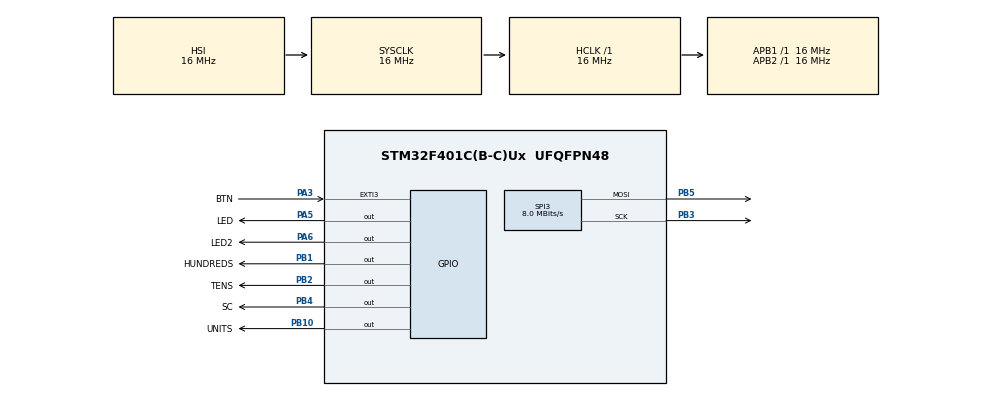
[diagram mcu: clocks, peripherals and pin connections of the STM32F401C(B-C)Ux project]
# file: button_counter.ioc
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Mcu.Family=STM32F4
Mcu.Name=STM32F401C(B-C)Ux
Mcu.Package=UFQFPN48
NVIC.EXTI3_IRQn=true\:0\:0\:false\:false\:true\:true\:true\:true
NVIC.PriorityGroup=NVIC_PRIORITYGROUP_4
PA13.Mode=Serial_Wire
PA13.Signal=SYS_JTMS-SWDIO
PA14.Mode=Serial_Wire
PA14.Signal=SYS_JTCK-SWCLK
PA3.GPIO_Label=BTN
PA3.GPIO_PuPd=GPIO_PULLDOWN
PA3.Signal=GPXTI3
PA5.GPIO_Label=LED
PA5.Signal=GPIO_Output
PA6.GPIO_Label=LED2
PA6.Signal=GPIO_Output
PB1.GPIO_Label=HUNDREDS
PB1.Signal=GPIO_Output
PB10.GPIO_Label=UNITS
PB10.Signal=GPIO_Output
PB2.GPIO_Label=TENS
PB2.Signal=GPIO_Output
PB3.Mode=TX_Only_Simplex_Unidirect_Master
PB3.Signal=SPI3_SCK
PB4.GPIO_Label=SC
PB4.Signal=GPIO_Output
PB5.Mode=TX_Only_Simplex_Unidirect_Master
PB5.Signal=SPI3_MOSI
ProjectManager.HeapSize=0x200
ProjectManager.StackSize=0x400
ProjectManager.TargetToolchain=STM32CubeIDE
RCC.AHBFreq_Value=16000000
RCC.APB1Freq_Value=16000000
RCC.APB2Freq_Value=16000000
RCC.CortexFreq_Value=16000000
RCC.HSE_VALUE=25000000
RCC.HSI_VALUE=16000000
RCC.LSE_VALUE=32768
RCC.SYSCLKFreq_VALUE=16000000
RCC.VCOOutputFreq_Value=192000000
SPI3.CalculateBaudRate=8.0 MBits/s
SPI3.Direction=SPI_DIRECTION_2LINES
SPI3.Mode=SPI_MODE_MASTER
SPI3.VirtualType=VM_MASTER
board=custom

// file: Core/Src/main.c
/* USER CODE BEGIN Header */
/**
  ******************************************************************************
  * @file           : main.c
  * @brief          : Main program body
  ******************************************************************************
  * @attention
  *
  * Copyright (c) 2025 STMicroelectronics.
  * All rights reserved.
  *
  * This software is licensed under terms that can be found in the LICENSE file
  * in the root directory of this software component.
  * If no LICENSE file comes with this software, it is provided AS-IS.
  *
  ******************************************************************************
  */
/* USER CODE END Header */
#include "main.h"

/* USER CODE BEGIN Includes */
#include "btn_counter.h" // Custom header for button counter logic / Пользовательский заголовок для логики счетчика кнопок

/* USER CODE END Includes */

SPI_HandleTypeDef hspi3;

/* USER CODE BEGIN PV */
//static uint16_t counter = 0;
/* USER CODE END PV */

void SystemClock_Config(void);
static void MX_GPIO_Init(void);
static void MX_SPI3_Init(void);

int main(void)
{

  /* MCU Configuration--------------------------------------------------------*/

  /* Reset of all peripherals, Initializes the Flash interface and the Systick. */
  HAL_Init();

  /* Configure the system clock */
  SystemClock_Config();

  /* Initialize all configured peripherals */
  MX_GPIO_Init();
  MX_SPI3_Init();
  /* USER CODE BEGIN 2 */

  //Initialize custom modules
  led_init(LED_GPIO_Port, LED_Pin); 			// Initialize LED control
  btn_init(BTN_Pin);							// Initialize button control
  transmit_init(&hspi3, SC_GPIO_Port, SC_Pin);	// Initialize SPI transmission

  // Configure display settings
  Display_InitTypeDef display_config =
  {
      .units_port = UNITS_GPIO_Port,
	  .units_pin = UNITS_Pin,
	  .tens_port = TENS_GPIO_Port,
	  .tens_pin = TENS_Pin,
	  .hundreds_port = HUNDREDS_GPIO_Port,
	  .hundreds_pin = HUNDREDS_Pin
  };
  display_init(&display_config); // Initialize display with configuration

  /* USER CODE END 2 */

  /* Infinite loop */
  /* USER CODE BEGIN WHILE */

  while (1)
  {
	  // Continuously update display with current counter value
	  update_display(get_counter());

    /* USER CODE END WHILE */

  }
}

void SystemClock_Config(void)
{
  RCC_OscInitTypeDef RCC_OscInitStruct = {0};
  RCC_ClkInitTypeDef RCC_ClkInitStruct = {0};

  /** Configure the main internal regulator output voltage
  */
  __HAL_RCC_PWR_CLK_ENABLE();
  __HAL_PWR_VOLTAGESCALING_CONFIG(PWR_REGULATOR_VOLTAGE_SCALE2);

  /** Initializes the RCC Oscillators according to the specified parameters
  * in the RCC_OscInitTypeDef structure.
  */
  RCC_OscInitStruct.OscillatorType = RCC_OSCILLATORTYPE_HSI;
  RCC_OscInitStruct.HSIState = RCC_HSI_ON;
  RCC_OscInitStruct.HSICalibrationValue = RCC_HSICALIBRATION_DEFAULT;
  RCC_OscInitStruct.PLL.PLLState = RCC_PLL_NONE;
  if (HAL_RCC_OscConfig(&RCC_OscInitStruct) != HAL_OK)
  {
    Error_Handler();
  }

  /** Initializes the CPU, AHB and APB buses clocks
  */
  RCC_ClkInitStruct.ClockType = RCC_CLOCKTYPE_HCLK|RCC_CLOCKTYPE_SYSCLK
                              |RCC_CLOCKTYPE_PCLK1|RCC_CLOCKTYPE_PCLK2;
  RCC_ClkInitStruct.SYSCLKSource = RCC_SYSCLKSOURCE_HSI;
  RCC_ClkInitStruct.AHBCLKDivider = RCC_SYSCLK_DIV1;
  RCC_ClkInitStruct.APB1CLKDivider = RCC_HCLK_DIV1;
  RCC_ClkInitStruct.APB2CLKDivider = RCC_HCLK_DIV1;

  if (HAL_RCC_ClockConfig(&RCC_ClkInitStruct, FLASH_LATENCY_0) != HAL_OK)
  {
    Error_Handler();
  }
}

static void MX_SPI3_Init(void)
{

  /* SPI3 parameter configuration*/
  hspi3.Instance = SPI3;
  hspi3.Init.Mode = SPI_MODE_MASTER;
  hspi3.Init.Direction = SPI_DIRECTION_2LINES;
  hspi3.Init.DataSize = SPI_DATASIZE_8BIT;
  hspi3.Init.CLKPolarity = SPI_POLARITY_LOW;
  hspi3.Init.CLKPhase = SPI_PHASE_1EDGE;
  hspi3.Init.NSS = SPI_NSS_SOFT;
  hspi3.Init.BaudRatePrescaler = SPI_BAUDRATEPRESCALER_2;
  hspi3.Init.FirstBit = SPI_FIRSTBIT_MSB;
  hspi3.Init.TIMode = SPI_TIMODE_DISABLE;
  hspi3.Init.CRCCalculation = SPI_CRCCALCULATION_DISABLE;
  hspi3.Init.CRCPolynomial = 10;
  if (HAL_SPI_Init(&hspi3) != HAL_OK)
  {
    Error_Handler();
  }

}

static void MX_GPIO_Init(void)
{
  GPIO_InitTypeDef GPIO_InitStruct = {0};

  /* GPIO Ports Clock Enable */
  __HAL_RCC_GPIOA_CLK_ENABLE();
  __HAL_RCC_GPIOB_CLK_ENABLE();

  /*Configure GPIO pin Output Level */
  HAL_GPIO_WritePin(GPIOA, LED_Pin|LED2_Pin, GPIO_PIN_RESET);

  /*Configure GPIO pin Output Level */
  HAL_GPIO_WritePin(GPIOB, HUNDREDS_Pin|TENS_Pin|UNITS_Pin|SC_Pin, GPIO_PIN_RESET);

  /*Configure GPIO pin : BTN_Pin */
  GPIO_InitStruct.Pin = BTN_Pin;
  GPIO_InitStruct.Mode = GPIO_MODE_IT_RISING;
  GPIO_InitStruct.Pull = GPIO_PULLDOWN;
  HAL_GPIO_Init(BTN_GPIO_Port, &GPIO_InitStruct);

  /*Configure GPIO pins : LED_Pin LED2_Pin */
  GPIO_InitStruct.Pin = LED_Pin|LED2_Pin;
  GPIO_InitStruct.Mode = GPIO_MODE_OUTPUT_PP;
  GPIO_InitStruct.Pull = GPIO_NOPULL;
  GPIO_InitStruct.Speed = GPIO_SPEED_FREQ_LOW;
  HAL_GPIO_Init(GPIOA, &GPIO_InitStruct);

  /*Configure GPIO pins : HUNDREDS_Pin TENS_Pin UNITS_Pin SC_Pin */
  GPIO_InitStruct.Pin = HUNDREDS_Pin|TENS_Pin|UNITS_Pin|SC_Pin;
  GPIO_InitStruct.Mode = GPIO_MODE_OUTPUT_PP;
  GPIO_InitStruct.Pull = GPIO_NOPULL;
  GPIO_InitStruct.Speed = GPIO_SPEED_FREQ_LOW;
  HAL_GPIO_Init(GPIOB, &GPIO_InitStruct);

  /* EXTI interrupt init*/
  HAL_NVIC_SetPriority(EXTI3_IRQn, 0, 0);
  HAL_NVIC_EnableIRQ(EXTI3_IRQn);

}

void Error_Handler(void)
{
  __disable_irq();
  while (1)
  {
  }
}
